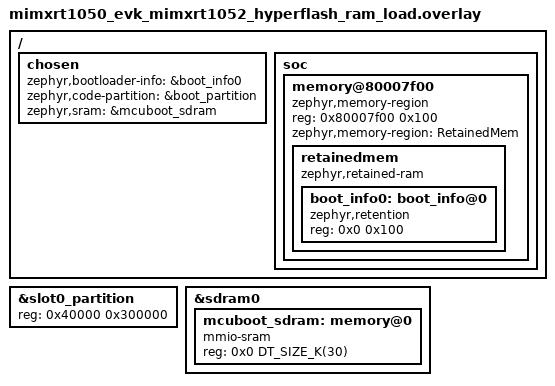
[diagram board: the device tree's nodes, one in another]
/ {
	chosen {
		zephyr,bootloader-info = &boot_info0;
		zephyr,code-partition = &boot_partition;
		zephyr,sram = &mcuboot_sdram;
	};

	soc {
		memory@80007f00 {
			compatible = "zephyr,memory-region", "mmio-sram";
			reg = <0x80007f00 0x100>;
			ranges = <0x0 0x80007f00 0x100>;
			zephyr,memory-region = "RetainedMem";
			status = "okay";
			#address-cells = <1>;
			#size-cells = <1>;

			retainedmem {
				compatible = "zephyr,retained-ram";
				status = "okay";
				ranges;
				#address-cells = <1>;
				#size-cells = <1>;

				boot_info0: boot_info@0 {
					compatible = "zephyr,retention";
					status = "okay";
					reg = <0x0 0x100>;
				};
			};
		};
	};
};

/* Reduce size of slot 0 to match slot 1 */
&slot0_partition {
	reg = <0x40000 0x300000>;
};

&sdram0 {
	#address-cells = <1>;
	#size-cells = <1>;

	mcuboot_sdram: memory@0 {
		compatible = "mmio-sram";
		reg = <0x0 DT_SIZE_K(30)>;
	};
};
